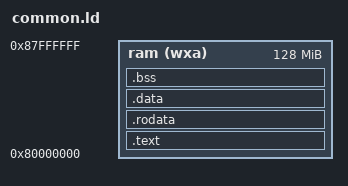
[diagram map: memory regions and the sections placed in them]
ENTRY(_start)

MEMORY
{
  ram   (wxa) : ORIGIN = 0x80000000, LENGTH = 128M
}

PHDRS
{
  text PT_LOAD;
  data PT_LOAD;
  bss PT_LOAD;
}

SECTIONS
{
  .text : {
    PROVIDE(_text_start = .);
    *(.text.init) *(.text .text.*)
    PROVIDE(_text_end = .);
  } >ram AT>ram :text

   PROVIDE(__global_pointer = .);
  .rodata : {
    PROVIDE(_rodata_start = .);
    *(.rodata .rodata.*)
    PROVIDE(_rodata_end = .);
  } >ram AT>ram :text

  .data : {
    . = ALIGN(4096);
    PROVIDE(_data_start = .);
    *(.sdata .sdata.*) *(.data .data.*)
    PROVIDE(_data_end = .);
  } >ram AT>ram :data

  .bss : {
    PROVIDE(_bss_start = .);
    *(.sbss .sbss.*) *(.bss .bss.*)
    PROVIDE(_bss_end = .);
  } >ram AT>ram :bss

  PROVIDE(__memory_start = ORIGIN(ram));
  PROVIDE(__stack_start = _bss_end);
  PROVIDE(__stack_end = __stack_start + 0x8000);
  PROVIDE(__memory_end = ORIGIN(ram) + LENGTH(ram));
  PROVIDE(__heap_start = __stack_end);
  PROVIDE(__heap_size = __memory_end - __heap_start);
  PROVIDE(__uart_base_addr = 0x10000000);
}
